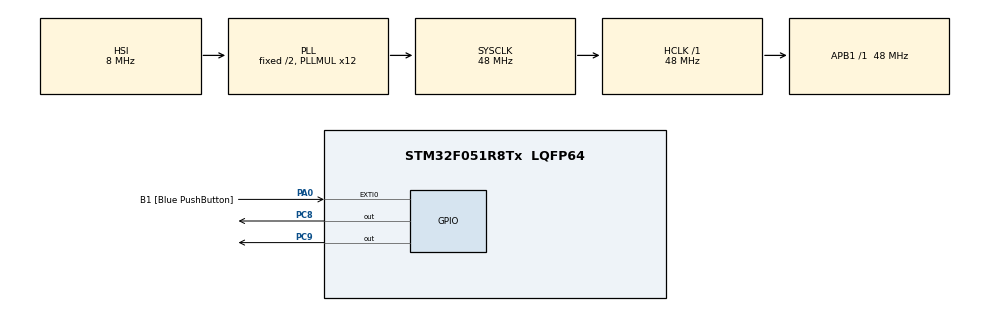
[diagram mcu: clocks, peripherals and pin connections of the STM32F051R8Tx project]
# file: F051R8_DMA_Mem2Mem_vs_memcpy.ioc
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Mcu.Family=STM32F0
Dma.MEMTOMEM.0.MemDataAlignment=DMA_MDATAALIGN_BYTE
Dma.MEMTOMEM.0.Priority=DMA_PRIORITY_LOW
PA14.GPIO_Label=SWCLK
PA0.GPIO_Label=B1 [Blue PushButton]
PC8.Signal=GPIO_Output
RCC.SYSCLKSource=RCC_SYSCLKSOURCE_PLLCLK
ProjectManager.StackSize=0x400
PA13.Signal=SYS_SWDIO
ProjectManager.TargetToolchain=STM32CubeIDE
RCC.HCLKFreq_Value=48000000
RCC.AHBFreq_Value=48000000
board=STM32F0DISCOVERY
RCC.PLLMUL=RCC_PLL_MUL12
PA14.Mode=Serial_Wire
PA0.GPIO_ModeDefaultEXTI=GPIO_MODE_EVT_RISING
Dma.MEMTOMEM.0.Instance=DMA1_Channel1
PA13.Mode=Serial_Wire
Mcu.Name=STM32F051R8Tx
PA13.GPIO_Label=SWDIO
PA0.Signal=GPXTI0
Dma.MEMTOMEM.0.PeriphDataAlignment=DMA_PDATAALIGN_BYTE
RCC.SYSCLKFreq_VALUE=48000000
Mcu.Package=LQFP64
Dma.MEMTOMEM.0.Mode=DMA_NORMAL
Dma.MEMTOMEM.0.MemInc=DMA_MINC_ENABLE
Dma.MEMTOMEM.0.PeriphInc=DMA_PINC_ENABLE
PA14.Signal=SYS_SWCLK
ProjectManager.HeapSize=0x200
RCC.APB1TimFreq_Value=48000000
Dma.MEMTOMEM.0.Direction=DMA_MEMORY_TO_MEMORY
PC9.Signal=GPIO_Output
NVIC.DMA1_Channel1_IRQn=true\:0\:0\:false\:false\:true\:true\:true
Dma.Request0=MEMTOMEM
RCC.APB1Freq_Value=48000000

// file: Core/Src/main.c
/* USER CODE BEGIN Header */
/**
  ******************************************************************************
  * @file           : main.c
  * @brief          : Main program body
  ******************************************************************************
  * @attention
  *
  * <h2><center>&copy; Copyright (c) 2021 STMicroelectronics.
  * All rights reserved.</center></h2>
  *
  * This software component is licensed by ST under BSD 3-Clause license,
  * the "License"; You may not use this file except in compliance with the
  * License. You may obtain a copy of the License at:
  *                        opensource.org/licenses/BSD-3-Clause
  *
  ******************************************************************************
  */
/* USER CODE END Header */
#include "main.h"

/* USER CODE BEGIN Includes */
#include <string.h>
/* USER CODE END Includes */

/* USER CODE BEGIN PD */
#define USE_DMA_INTERRUPT
#define USE_DMA_WORD_ALIGN
/* USER CODE END PD */

DMA_HandleTypeDef hdma_memtomem_dma1_channel1;
/* USER CODE BEGIN PV */
#define TRANSFER_SIZE   4096
const char flash_data[TRANSFER_SIZE] = "hello";
char sram_buffer[TRANSFER_SIZE];
/* USER CODE END PV */

void SystemClock_Config(void);
static void MX_GPIO_Init(void);
static void MX_DMA_Init(void);

/* USER CODE BEGIN 0 */
void DMA_HalfTransferCallback(DMA_HandleTypeDef * _hdma) {
  HAL_GPIO_WritePin(GPIOC, GPIO_PIN_8, GPIO_PIN_SET);
}
void DMA_FullTransferCallback(DMA_HandleTypeDef * _hdma) {
  HAL_GPIO_WritePin(GPIOC, GPIO_PIN_8, GPIO_PIN_RESET);
  HAL_GPIO_WritePin(GPIOC, GPIO_PIN_9, GPIO_PIN_RESET);
}
/* USER CODE END 0 */

int main(void)
{

  /* MCU Configuration--------------------------------------------------------*/

  /* Reset of all peripherals, Initializes the Flash interface and the Systick. */
  HAL_Init();

  /* Configure the system clock */
  SystemClock_Config();

  /* Initialize all configured peripherals */
  MX_GPIO_Init();
  MX_DMA_Init();

  /* Infinite loop */
  /* USER CODE BEGIN WHILE */
  HAL_GPIO_WritePin(GPIOC, GPIO_PIN_9, GPIO_PIN_RESET);
  HAL_GPIO_WritePin(GPIOC, GPIO_PIN_8, GPIO_PIN_RESET);
  HAL_Delay(500);

  HAL_Delay(1);
  HAL_GPIO_WritePin(GPIOC, GPIO_PIN_9, GPIO_PIN_SET);
  memcpy(&sram_buffer, &flash_data, TRANSFER_SIZE);
  HAL_GPIO_WritePin(GPIOC, GPIO_PIN_9, GPIO_PIN_RESET);

#ifdef USE_DMA_INTERRUPT
  HAL_Delay(1);
  HAL_GPIO_WritePin(GPIOC, GPIO_PIN_9, GPIO_PIN_SET);
  HAL_DMA_RegisterCallback(&hdma_memtomem_dma1_channel1, HAL_DMA_XFER_HALFCPLT_CB_ID, DMA_HalfTransferCallback);
  HAL_DMA_RegisterCallback(&hdma_memtomem_dma1_channel1, HAL_DMA_XFER_CPLT_CB_ID, DMA_FullTransferCallback);
#ifdef USE_DMA_WORD_ALIGN
  HAL_DMA_Start_IT(&hdma_memtomem_dma1_channel1, (uint32_t)&flash_data, (uint32_t)&sram_buffer, TRANSFER_SIZE/4);
#else
  HAL_DMA_Start_IT(&hdma_memtomem_dma1_channel1, (uint32_t)&flash_data, (uint32_t)&sram_buffer, TRANSFER_SIZE);
#endif
#else
  HAL_Delay(1);
  HAL_GPIO_WritePin(GPIOC, GPIO_PIN_9, GPIO_PIN_SET);
  HAL_DMA_Start(&hdma_memtomem_dma1_channel1, (uint32_t)&flash_data, (uint32_t)&sram_buffer, TRANSFER_SIZE);
  HAL_DMA_PollForTransfer(&hdma_memtomem_dma1_channel1, HAL_DMA_FULL_TRANSFER, HAL_MAX_DELAY);
  HAL_GPIO_WritePin(GPIOC, GPIO_PIN_9, GPIO_PIN_RESET);
#endif

  HAL_Delay(500);
  while (1)
  {
    HAL_GPIO_TogglePin(GPIOC, GPIO_PIN_9);
    HAL_Delay(500);
    /* USER CODE END WHILE */

  }
}

void SystemClock_Config(void)
{
  RCC_OscInitTypeDef RCC_OscInitStruct = {0};
  RCC_ClkInitTypeDef RCC_ClkInitStruct = {0};

  /** Initializes the RCC Oscillators according to the specified parameters
  * in the RCC_OscInitTypeDef structure.
  */
  RCC_OscInitStruct.OscillatorType = RCC_OSCILLATORTYPE_HSI;
  RCC_OscInitStruct.HSIState = RCC_HSI_ON;
  RCC_OscInitStruct.HSICalibrationValue = RCC_HSICALIBRATION_DEFAULT;
  RCC_OscInitStruct.PLL.PLLState = RCC_PLL_ON;
  RCC_OscInitStruct.PLL.PLLSource = RCC_PLLSOURCE_HSI;
  RCC_OscInitStruct.PLL.PLLMUL = RCC_PLL_MUL12;
  RCC_OscInitStruct.PLL.PREDIV = RCC_PREDIV_DIV1;
  if (HAL_RCC_OscConfig(&RCC_OscInitStruct) != HAL_OK)
  {
    Error_Handler();
  }
  /** Initializes the CPU, AHB and APB buses clocks
  */
  RCC_ClkInitStruct.ClockType = RCC_CLOCKTYPE_HCLK|RCC_CLOCKTYPE_SYSCLK
                              |RCC_CLOCKTYPE_PCLK1;
  RCC_ClkInitStruct.SYSCLKSource = RCC_SYSCLKSOURCE_PLLCLK;
  RCC_ClkInitStruct.AHBCLKDivider = RCC_SYSCLK_DIV1;
  RCC_ClkInitStruct.APB1CLKDivider = RCC_HCLK_DIV1;

  if (HAL_RCC_ClockConfig(&RCC_ClkInitStruct, FLASH_LATENCY_1) != HAL_OK)
  {
    Error_Handler();
  }
}

static void MX_DMA_Init(void)
{

  /* DMA controller clock enable */
  __HAL_RCC_DMA1_CLK_ENABLE();

  /* Configure DMA request hdma_memtomem_dma1_channel1 on DMA1_Channel1 */
  hdma_memtomem_dma1_channel1.Instance = DMA1_Channel1;
  hdma_memtomem_dma1_channel1.Init.Direction = DMA_MEMORY_TO_MEMORY;
  hdma_memtomem_dma1_channel1.Init.PeriphInc = DMA_PINC_ENABLE;
  hdma_memtomem_dma1_channel1.Init.MemInc = DMA_MINC_ENABLE;
#ifdef USE_DMA_WORD_ALIGN
  hdma_memtomem_dma1_channel1.Init.PeriphDataAlignment = DMA_PDATAALIGN_WORD;
  hdma_memtomem_dma1_channel1.Init.MemDataAlignment = DMA_MDATAALIGN_WORD;
#else
  hdma_memtomem_dma1_channel1.Init.PeriphDataAlignment = DMA_PDATAALIGN_BYTE;
  hdma_memtomem_dma1_channel1.Init.MemDataAlignment = DMA_MDATAALIGN_BYTE;
#endif
  hdma_memtomem_dma1_channel1.Init.Mode = DMA_NORMAL;
  hdma_memtomem_dma1_channel1.Init.Priority = DMA_PRIORITY_LOW;
  if (HAL_DMA_Init(&hdma_memtomem_dma1_channel1) != HAL_OK)
  {
    Error_Handler( );
  }

  /* DMA interrupt init */
  /* DMA1_Channel1_IRQn interrupt configuration */
  HAL_NVIC_SetPriority(DMA1_Channel1_IRQn, 0, 0);
  HAL_NVIC_EnableIRQ(DMA1_Channel1_IRQn);

}

static void MX_GPIO_Init(void)
{
  GPIO_InitTypeDef GPIO_InitStruct = {0};

  /* GPIO Ports Clock Enable */
  __HAL_RCC_GPIOA_CLK_ENABLE();
  __HAL_RCC_GPIOC_CLK_ENABLE();

  /*Configure GPIO pin Output Level */
  HAL_GPIO_WritePin(GPIOC, GPIO_PIN_8|GPIO_PIN_9, GPIO_PIN_RESET);

  /*Configure GPIO pin : B1_Pin */
  GPIO_InitStruct.Pin = B1_Pin;
  GPIO_InitStruct.Mode = GPIO_MODE_EVT_RISING;
  GPIO_InitStruct.Pull = GPIO_NOPULL;
  HAL_GPIO_Init(B1_GPIO_Port, &GPIO_InitStruct);

  /*Configure GPIO pins : PC8 PC9 */
  GPIO_InitStruct.Pin = GPIO_PIN_8|GPIO_PIN_9;
  GPIO_InitStruct.Mode = GPIO_MODE_OUTPUT_PP;
  GPIO_InitStruct.Pull = GPIO_NOPULL;
  GPIO_InitStruct.Speed = GPIO_SPEED_FREQ_LOW;
  HAL_GPIO_Init(GPIOC, &GPIO_InitStruct);

}

void Error_Handler(void)
{
  __disable_irq();
  while (1)
  {
  }
}

/************************ (C) COPYRIGHT STMicroelectronics *****END OF FILE****/
